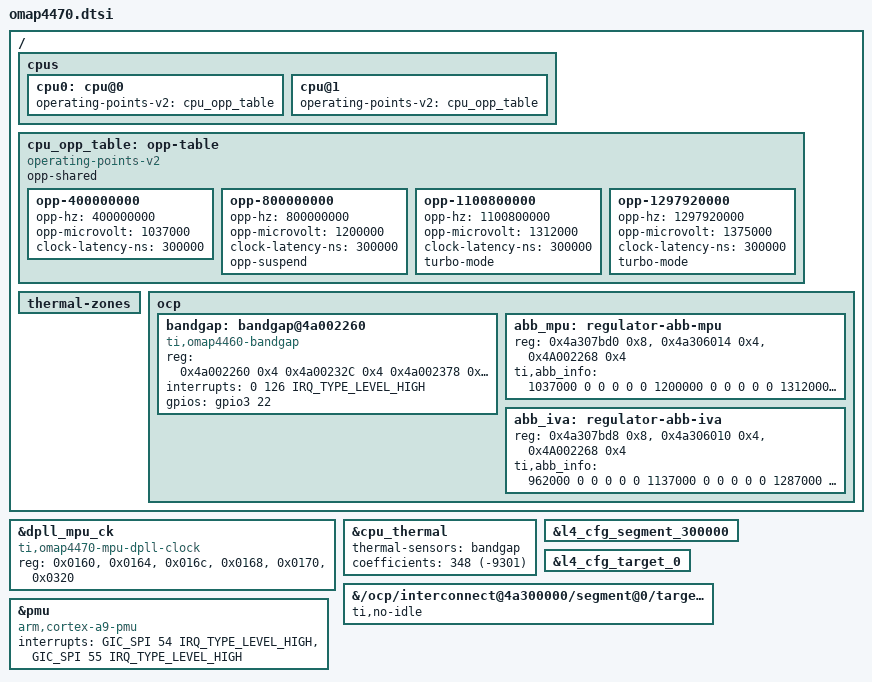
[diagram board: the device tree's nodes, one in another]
// SPDX-License-Identifier: GPL-2.0-only
/*
 * Device Tree Source for OMAP4470 SoC
 *
 * Copyright (C) 2012 Texas Instruments Incorporated - https://www.ti.com/
 */
#include "omap4.dtsi"

/ {
	cpus {
		cpu0: cpu@0 {
			operating-points-v2 = <&cpu_opp_table>;

			/* cooling options */
			#cooling-cells = <2>; /* min followed by max */
		};

		cpu@1 {
			operating-points-v2 = <&cpu_opp_table>;
		};
	};

	/*
	 * MPU OPPs from SWPU325 Tables 2-1 and 2-2, rates from TRM Table 3-88
	 * (SYS_CLK 38.4 MHz). OPP50 and OPP100 share one DPLL_MPU lock (Fdpll
	 * 1.6 GHz) and differ only in M2; OPPTB and OPPNT lock at the MPU rate
	 * and use CLKOUTX2_M3 with the DCC. Those two are boost OPPs: off
	 * until /sys/devices/system/cpu/cpufreq/boost is set.
	 *
	 * OPPNTSB (1497.6 MHz, 1.387 V) is left out. SWPU325 requires ABB
	 * there, and the only mode the TRM gives for it is Set2 (RBB), which
	 * needs the MPU_RBB_NTSB trim (TRM §3.8.4.3.3). Without ABB, AVS on a
	 * warm 1.5 GHz part settles above the nominal.
	 */
	cpu_opp_table: opp-table {
		compatible = "operating-points-v2";
		opp-shared;

		opp-400000000 {
			opp-hz = /bits/ 64 <400000000>;
			opp-microvolt = <1037000>;
			clock-latency-ns = <300000>;
		};

		/* Suspend from the bootloader's OPP: no DCC, ABB bypass */
		opp-800000000 {
			opp-hz = /bits/ 64 <800000000>;
			opp-microvolt = <1200000>;
			clock-latency-ns = <300000>;
			opp-suspend;
		};

		opp-1100800000 {
			opp-hz = /bits/ 64 <1100800000>;
			opp-microvolt = <1312000>;
			clock-latency-ns = <300000>;
			turbo-mode;
		};

		opp-1297920000 {
			opp-hz = /bits/ 64 <1297920000>;
			opp-microvolt = <1375000>;
			clock-latency-ns = <300000>;
			turbo-mode;
		};
	};

	/* From 4460 */
	thermal-zones {
		#include "omap4-cpu-thermal.dtsi"
	};

	/* From 4460 */
	ocp {
		bandgap: bandgap@4a002260 {
			reg = <0x4a002260 0x4
			       0x4a00232C 0x4
			       0x4a002378 0x18>;
			compatible = "ti,omap4460-bandgap";
			interrupts = <0 126 IRQ_TYPE_LEVEL_HIGH>; /* talert */
			gpios = <&gpio3 22 GPIO_ACTIVE_HIGH>; /* tshut */

			#thermal-sensor-cells = <0>;
		};

		abb_mpu: regulator-abb-mpu {
			status = "okay";

			reg = <0x4a307bd0 0x8>, <0x4a306014 0x4>,
			      <0x4A002268 0x4>;
			reg-names = "base-address", "int-address",
				    "efuse-address";

			/*
			 * ABB per TRM §3.8.4.3 and Table 3-363: RBB (Set2) at
			 * TURBO/NITRO/NTSB when CONTROL_STD_FUSE_OPP_DPLL_1
			 * says it is trimmed; otherwise FBB (Set1) at NITRO
			 * and bypass at TURBO and NTSB.
			 */
			ti,abb_info = <
				/*uV		ABB	efuse	rbb_m		fbb_m	vset_m*/
				1037000		0	0		0			0		0
				1200000		0	0		0			0		0
				1312000		0	0		0x100000	0		0
				1375000		1	0		0x400000	0		0
				1387000		0	0		0x800000	0		0
			>;
		};

		abb_iva: regulator-abb-iva {
			status = "okay";

			reg = <0x4a307bd8 0x8>, <0x4a306010 0x4>,
			      <0x4A002268 0x4>;
			reg-names = "base-address", "int-address",
				    "efuse-address";

			ti,abb_info = <
				/*uV		ABB	efuse	rbb_m		fbb_m	vset_m*/
				962000		0	0		0			0		0
				1137000		0	0		0			0		0
				1287000		0	0		0x200000 	0		0
				1375000		1	0		0x1000000	0		0
				1380000		0	0		0x2000000	0		0
			>;
		};
	};
};

/*
 * dpll_mpu_ck is MPU_DPLL_CLK: CLKOUT_M2 below 1 GHz, CLKOUTX2_M3 through
 * the DCC above. The extra registers are CM_DIV_M2_DPLL_MPU and
 * CM_MPU_MPU_CLKCTRL (bridge dividers). The driver owns M2, so the
 * dpll_mpu_m2_ck divider goes.
 */
&dpll_mpu_ck {
	compatible = "ti,omap4470-mpu-dpll-clock";
	reg = <0x0160>, <0x0164>, <0x016c>, <0x0168>, <0x0170>, <0x0320>;
};

/delete-node/ &dpll_mpu_m2_ck;

&cpu_thermal {
	thermal-sensors = <&bandgap>;
	coefficients = <348 (-9301)>;
};

/* Only some L4 CFG interconnect ranges are different on 4460 */
&l4_cfg_segment_300000 {
	ranges = <0x00000000 0x00300000 0x020000>,	/* ap 67 */
		 <0x00040000 0x00340000 0x001000>,	/* ap 68 */
		 <0x00020000 0x00320000 0x004000>,	/* ap 71 */
		 <0x00024000 0x00324000 0x002000>,	/* ap 72 */
		 <0x00026000 0x00326000 0x001000>,	/* ap 73 */
		 <0x00027000 0x00327000 0x001000>,	/* ap 74 */
		 <0x00028000 0x00328000 0x001000>,	/* ap 75 */
		 <0x00029000 0x00329000 0x001000>,	/* ap 76 */
		 <0x00030000 0x00330000 0x010000>,	/* ap 77 */
		 <0x0002a000 0x0032a000 0x002000>,	/* ap 90 */
		 <0x0002c000 0x0032c000 0x004000>,	/* ap 91 */
		 <0x00010000 0x00310000 0x008000>,	/* ap 92 */
		 <0x00018000 0x00318000 0x004000>,	/* ap 93 */
		 <0x0001c000 0x0031c000 0x002000>,	/* ap 94 */
		 <0x0001e000 0x0031e000 0x002000>;	/* ap 95 */
};

&l4_cfg_target_0 {
	ranges = <0x00000000 0x00000000 0x00010000>,
		 <0x00010000 0x00010000 0x00008000>,
		 <0x00018000 0x00018000 0x00004000>,
		 <0x0001c000 0x0001c000 0x00002000>,
		 <0x0001e000 0x0001e000 0x00002000>,
		 <0x00020000 0x00020000 0x00004000>,
		 <0x00024000 0x00024000 0x00002000>,
		 <0x00026000 0x00026000 0x00001000>,
		 <0x00027000 0x00027000 0x00001000>,
		 <0x00028000 0x00028000 0x00001000>,
		 <0x00029000 0x00029000 0x00001000>,
		 <0x0002a000 0x0002a000 0x00002000>,
		 <0x0002c000 0x0002c000 0x00004000>,
		 <0x00030000 0x00030000 0x00010000>;
};

/*
 * 32k sync counter (clocksource and sched_clock): keep it in no-idle while
 * running. In force-idle its L4_WKUP interface clock gates between reads,
 * and a 32KSYNCNT_CR read right after the clock restarts can return a wrong
 * value (erratum i103); reads then lag real time by up to ~800 ms. The MPU
 * has no static dependency on CD_WKUP to keep that clock running.
 * timer-ti-32k switches it to force-idle for suspend.
 */
&{/ocp/interconnect@4a300000/segment@0/target-module@4000} {
	ti,no-idle;
};

&pmu {
	compatible = "arm,cortex-a9-pmu";
	interrupts = <GIC_SPI 54 IRQ_TYPE_LEVEL_HIGH>,
		     <GIC_SPI 55 IRQ_TYPE_LEVEL_HIGH>;
};

/include/ "omap446x-clocks.dtsi"
